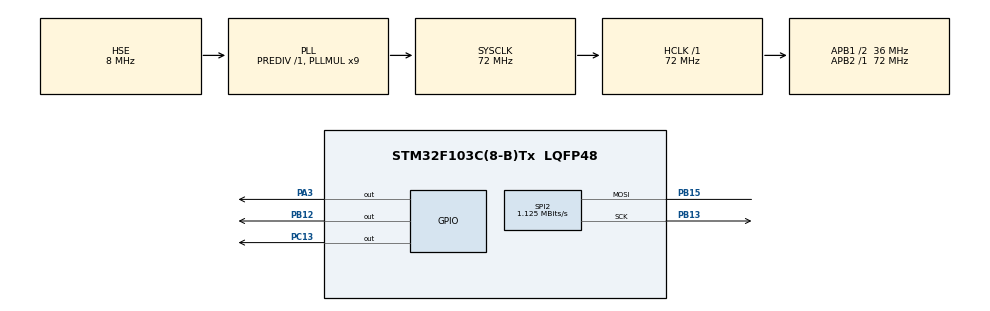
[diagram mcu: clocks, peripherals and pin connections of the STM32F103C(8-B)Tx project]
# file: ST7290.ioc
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Mcu.Family=STM32F1
Mcu.Name=STM32F103C(8-B)Tx
Mcu.Package=LQFP48
NVIC.PriorityGroup=NVIC_PRIORITYGROUP_4
PA13.Mode=Serial_Wire
PA13.Signal=SYS_JTMS-SWDIO
PA14.Mode=Serial_Wire
PA14.Signal=SYS_JTCK-SWCLK
PA3.Signal=GPIO_Output
PB12.Signal=GPIO_Output
PB13.Mode=Simplex_Bidirectional_Master
PB13.Signal=SPI2_SCK
PB15.Mode=Simplex_Bidirectional_Master
PB15.Signal=SPI2_MOSI
PC13-TAMPER-RTC.Signal=GPIO_Output
PD0-OSC_IN.Mode=HSE-External-Oscillator
PD0-OSC_IN.Signal=RCC_OSC_IN
PD1-OSC_OUT.Mode=HSE-External-Oscillator
PD1-OSC_OUT.Signal=RCC_OSC_OUT
ProjectManager.HeapSize=0x200
ProjectManager.StackSize=0x400
ProjectManager.TargetToolchain=STM32CubeIDE
RCC.AHBFreq_Value=72000000
RCC.APB1CLKDivider=RCC_HCLK_DIV2
RCC.APB1Freq_Value=36000000
RCC.APB1TimFreq_Value=72000000
RCC.APB2Freq_Value=72000000
RCC.APB2TimFreq_Value=72000000
RCC.HCLKFreq_Value=72000000
RCC.PLLMUL=RCC_PLL_MUL9
RCC.PLLSourceVirtual=RCC_PLLSOURCE_HSE
RCC.SYSCLKFreq_VALUE=72000000
RCC.SYSCLKSource=RCC_SYSCLKSOURCE_PLLCLK
RCC.USBFreq_Value=72000000
SPI2.BaudRatePrescaler=SPI_BAUDRATEPRESCALER_32
SPI2.CalculateBaudRate=1.125 MBits/s
SPI2.Direction=SPI_DIRECTION_1LINE
SPI2.Mode=SPI_MODE_MASTER
SPI2.VirtualType=VM_MASTER
TIM4.Period=0xffff-1
TIM4.Prescaler=72-1
VP_TIM4_VS_ClockSourceINT.Mode=Internal
board=custom

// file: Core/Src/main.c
/* USER CODE BEGIN Header */
/**
  ******************************************************************************
  * @file           : main.c
  * @brief          : Main program body
  ******************************************************************************
  * @attention
  *
  * <h2><center>&copy; Copyright (c) 2021 STMicroelectronics.
  * All rights reserved.</center></h2>
  *
  * This software component is licensed by ST under BSD 3-Clause license,
  * the "License"; You may not use this file except in compliance with the
  * License. You may obtain a copy of the License at:
  *                        opensource.org/licenses/BSD-3-Clause
  *
  ******************************************************************************
  */
/* USER CODE END Header */

#include "main.h"

/* USER CODE BEGIN Includes */
#include "ST7920_SERIAL.h"
#include "delay.h"
/* USER CODE END Includes */

SPI_HandleTypeDef hspi2;

TIM_HandleTypeDef htim4;

void SystemClock_Config(void);
static void MX_GPIO_Init(void);
static void MX_TIM4_Init(void);
static void MX_SPI2_Init(void);

int main(void)
{

  /* MCU Configuration--------------------------------------------------------*/

  /* Reset of all peripherals, Initializes the Flash interface and the Systick. */
  HAL_Init();

  /* Configure the system clock */
  SystemClock_Config();

  /* Initialize all configured peripherals */
  MX_GPIO_Init();
  MX_TIM4_Init();
  MX_SPI2_Init();
  /* USER CODE BEGIN 2 */
  delay_init();
	ST7920_Init(&hspi2, GPIOB, GPIO_PIN_12);
  /* USER CODE END 2 */

  /* Infinite loop */
  while (1)
  {

		/* USER CODE BEGIN 3 */
		ST7920_SendString(0,0, "HELLO WORLD");
		ST7920_SendString(1,0, "FROM");
		ST7920_SendString(2,0, "CONTROLLERSTECH");
		ST7920_SendString(3,0, "1234567890!@#$%^");

		HAL_Delay(2000);
  }
  /* USER CODE END 3 */
}

void SystemClock_Config(void)
{
  RCC_OscInitTypeDef RCC_OscInitStruct = {0};
  RCC_ClkInitTypeDef RCC_ClkInitStruct = {0};

  /** Initializes the CPU, AHB and APB busses clocks
  */
  RCC_OscInitStruct.OscillatorType = RCC_OSCILLATORTYPE_HSE;
  RCC_OscInitStruct.HSEState = RCC_HSE_ON;
  RCC_OscInitStruct.HSEPredivValue = RCC_HSE_PREDIV_DIV1;
  RCC_OscInitStruct.HSIState = RCC_HSI_ON;
  RCC_OscInitStruct.PLL.PLLState = RCC_PLL_ON;
  RCC_OscInitStruct.PLL.PLLSource = RCC_PLLSOURCE_HSE;
  RCC_OscInitStruct.PLL.PLLMUL = RCC_PLL_MUL9;
  if (HAL_RCC_OscConfig(&RCC_OscInitStruct) != HAL_OK)
  {
    Error_Handler();
  }
  /** Initializes the CPU, AHB and APB busses clocks
  */
  RCC_ClkInitStruct.ClockType = RCC_CLOCKTYPE_HCLK|RCC_CLOCKTYPE_SYSCLK
                              |RCC_CLOCKTYPE_PCLK1|RCC_CLOCKTYPE_PCLK2;
  RCC_ClkInitStruct.SYSCLKSource = RCC_SYSCLKSOURCE_PLLCLK;
  RCC_ClkInitStruct.AHBCLKDivider = RCC_SYSCLK_DIV1;
  RCC_ClkInitStruct.APB1CLKDivider = RCC_HCLK_DIV2;
  RCC_ClkInitStruct.APB2CLKDivider = RCC_HCLK_DIV1;

  if (HAL_RCC_ClockConfig(&RCC_ClkInitStruct, FLASH_LATENCY_2) != HAL_OK)
  {
    Error_Handler();
  }
}

static void MX_SPI2_Init(void)
{

  /* SPI2 parameter configuration*/
  hspi2.Instance = SPI2;
  hspi2.Init.Mode = SPI_MODE_MASTER;
  hspi2.Init.Direction = SPI_DIRECTION_1LINE;
  hspi2.Init.DataSize = SPI_DATASIZE_8BIT;
  hspi2.Init.CLKPolarity = SPI_POLARITY_LOW;
  hspi2.Init.CLKPhase = SPI_PHASE_1EDGE;
  hspi2.Init.NSS = SPI_NSS_SOFT;
  hspi2.Init.BaudRatePrescaler = SPI_BAUDRATEPRESCALER_32;
  hspi2.Init.FirstBit = SPI_FIRSTBIT_MSB;
  hspi2.Init.TIMode = SPI_TIMODE_DISABLE;
  hspi2.Init.CRCCalculation = SPI_CRCCALCULATION_DISABLE;
  hspi2.Init.CRCPolynomial = 10;
  if (HAL_SPI_Init(&hspi2) != HAL_OK)
  {
    Error_Handler();
  }

}

static void MX_TIM4_Init(void)
{

  TIM_ClockConfigTypeDef sClockSourceConfig = {0};
  TIM_MasterConfigTypeDef sMasterConfig = {0};

  htim4.Instance = TIM4;
  htim4.Init.Prescaler = 72-1;
  htim4.Init.CounterMode = TIM_COUNTERMODE_UP;
  htim4.Init.Period = 0xffff-1;
  htim4.Init.ClockDivision = TIM_CLOCKDIVISION_DIV1;
  htim4.Init.AutoReloadPreload = TIM_AUTORELOAD_PRELOAD_DISABLE;
  if (HAL_TIM_Base_Init(&htim4) != HAL_OK)
  {
    Error_Handler();
  }
  sClockSourceConfig.ClockSource = TIM_CLOCKSOURCE_INTERNAL;
  if (HAL_TIM_ConfigClockSource(&htim4, &sClockSourceConfig) != HAL_OK)
  {
    Error_Handler();
  }
  sMasterConfig.MasterOutputTrigger = TIM_TRGO_RESET;
  sMasterConfig.MasterSlaveMode = TIM_MASTERSLAVEMODE_DISABLE;
  if (HAL_TIMEx_MasterConfigSynchronization(&htim4, &sMasterConfig) != HAL_OK)
  {
    Error_Handler();
  }

}

static void MX_GPIO_Init(void)
{
  GPIO_InitTypeDef GPIO_InitStruct = {0};

  /* GPIO Ports Clock Enable */
  __HAL_RCC_GPIOC_CLK_ENABLE();
  __HAL_RCC_GPIOD_CLK_ENABLE();
  __HAL_RCC_GPIOA_CLK_ENABLE();
  __HAL_RCC_GPIOB_CLK_ENABLE();

  /*Configure GPIO pin Output Level */
  HAL_GPIO_WritePin(GPIOC, GPIO_PIN_13, GPIO_PIN_RESET);

  /*Configure GPIO pin Output Level */
  HAL_GPIO_WritePin(GPIOA, GPIO_PIN_3, GPIO_PIN_RESET);

  /*Configure GPIO pin Output Level */
  HAL_GPIO_WritePin(GPIOB, GPIO_PIN_12, GPIO_PIN_RESET);

  /*Configure GPIO pin : PC13 */
  GPIO_InitStruct.Pin = GPIO_PIN_13;
  GPIO_InitStruct.Mode = GPIO_MODE_OUTPUT_PP;
  GPIO_InitStruct.Pull = GPIO_NOPULL;
  GPIO_InitStruct.Speed = GPIO_SPEED_FREQ_LOW;
  HAL_GPIO_Init(GPIOC, &GPIO_InitStruct);

  /*Configure GPIO pin : PA3 */
  GPIO_InitStruct.Pin = GPIO_PIN_3;
  GPIO_InitStruct.Mode = GPIO_MODE_OUTPUT_PP;
  GPIO_InitStruct.Pull = GPIO_NOPULL;
  GPIO_InitStruct.Speed = GPIO_SPEED_FREQ_LOW;
  HAL_GPIO_Init(GPIOA, &GPIO_InitStruct);

  /*Configure GPIO pin : PB12 */
  GPIO_InitStruct.Pin = GPIO_PIN_12;
  GPIO_InitStruct.Mode = GPIO_MODE_OUTPUT_PP;
  GPIO_InitStruct.Pull = GPIO_NOPULL;
  GPIO_InitStruct.Speed = GPIO_SPEED_FREQ_LOW;
  HAL_GPIO_Init(GPIOB, &GPIO_InitStruct);

}

void Error_Handler(void)
{
}

/************************ (C) COPYRIGHT STMicroelectronics *****END OF FILE****/
